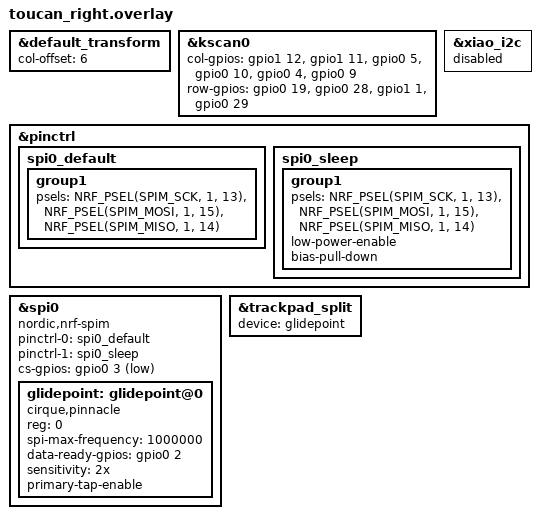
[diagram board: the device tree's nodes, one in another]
#include "toucan.dtsi"

&default_transform {
    col-offset = <6>;
};

&kscan0 {
    col-gpios
    = <&gpio1 12 GPIO_ACTIVE_HIGH>
    , <&gpio1 11 GPIO_ACTIVE_HIGH>
    , <&gpio0 5 GPIO_ACTIVE_HIGH>
    , <&gpio0 10 GPIO_ACTIVE_HIGH>
    , <&gpio0 4 GPIO_ACTIVE_HIGH>
    , <&gpio0 9 GPIO_ACTIVE_HIGH>
    ;

    row-gpios
    = <&gpio0 19 (GPIO_ACTIVE_HIGH | GPIO_PULL_DOWN)>
    , <&gpio0 28 (GPIO_ACTIVE_HIGH | GPIO_PULL_DOWN)>
    , <&gpio1 1 (GPIO_ACTIVE_HIGH | GPIO_PULL_DOWN)>
    , <&gpio0 29 (GPIO_ACTIVE_HIGH | GPIO_PULL_DOWN)>
    ;
};

/*
 * Circular trackpad: a Cirque Pinnacle on SPI. Pins and bus are beekeeb's
 * (zmk-keyboard-toucan); the driver is Zephyr's in-tree one, not the
 * cirque-input-module beekeeb builds with -- on Zephyr 4.1 that module's
 * bindings collide with the in-tree ones. The square-pad config (Azoteq TPS43 on I2C, from
 * zmk-keyboard-toucan2) uses the SAME pins -- P1.13/P1.15/P1.14 as
 * SDA/SCL/reset there, SCK/MOSI/MISO here -- so the wrong one builds, boots
 * and simply never hears from the pad.
 */
&xiao_i2c {
    status = "disabled";
};

&pinctrl {
    spi0_default: spi0_default {
        group1 {
            psels = <NRF_PSEL(SPIM_SCK, 1, 13)>,
                    <NRF_PSEL(SPIM_MOSI, 1, 15)>,
                    <NRF_PSEL(SPIM_MISO, 1, 14)>;
        };
    };

    spi0_sleep: spi0_sleep {
        group1 {
            psels = <NRF_PSEL(SPIM_SCK, 1, 13)>,
                    <NRF_PSEL(SPIM_MOSI, 1, 15)>,
                    <NRF_PSEL(SPIM_MISO, 1, 14)>;
            low-power-enable;
            bias-pull-down; // minimize power leakage during sleep
        };
    };
};

&spi0 {
    compatible = "nordic,nrf-spim";
    status = "okay";
    pinctrl-0 = <&spi0_default>;
    pinctrl-1 = <&spi0_sleep>;
    pinctrl-names = "default", "sleep";
    cs-gpios = <&gpio0 3 (GPIO_ACTIVE_LOW | GPIO_PULL_UP)>;  // pull-up keeps CS deasserted while asleep

    glidepoint: glidepoint@0 {
        compatible = "cirque,pinnacle";
        reg = <0>;
        spi-max-frequency = <1000000>;
        status = "okay";
        data-ready-gpios = <&gpio0 2 GPIO_ACTIVE_HIGH>;
        sensitivity = "2x";
        primary-tap-enable;     // tap to click, as beekeeb's driver does by default
        /* No invert-x: in-tree it applies to absolute mode only. The listener
           inverts X instead (toucan.dtsi). */
    };
};

&trackpad_split {
    device = <&glidepoint>;
};
